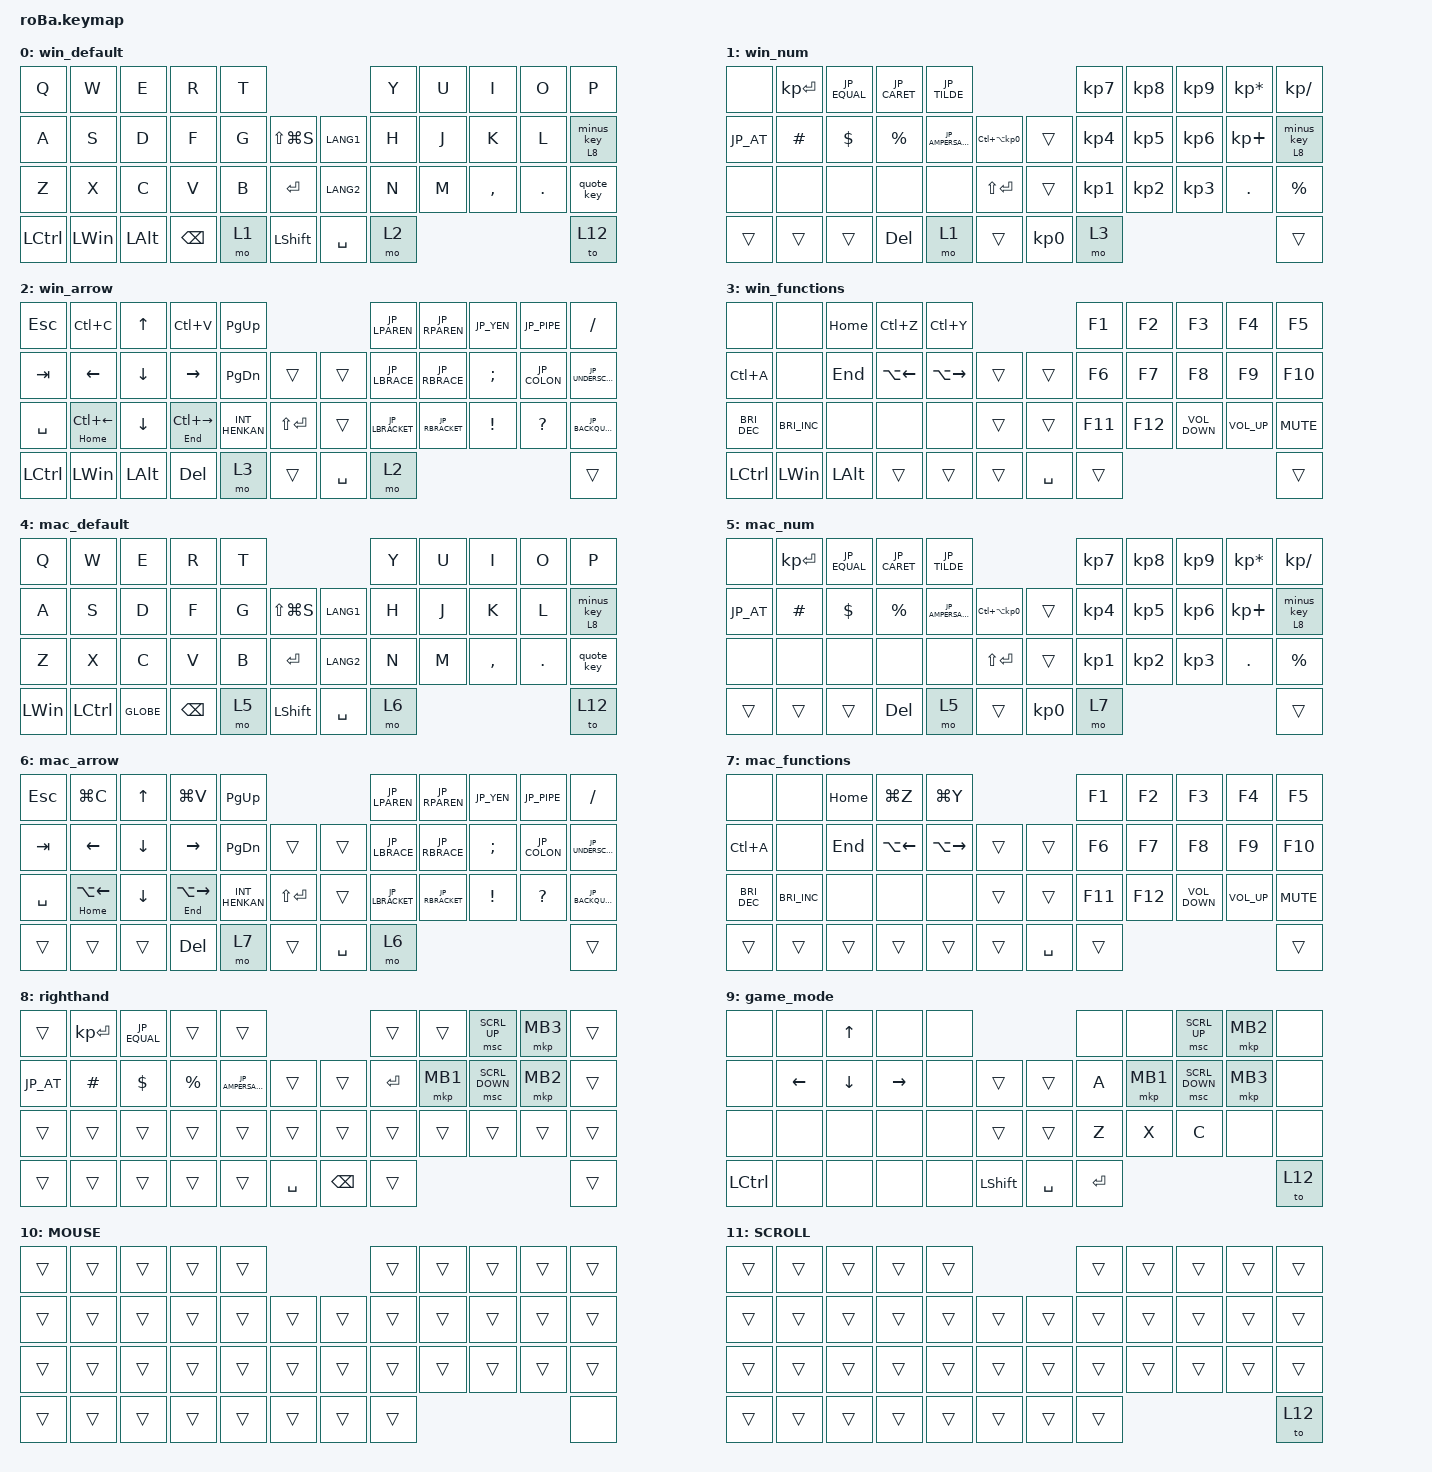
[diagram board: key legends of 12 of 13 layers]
// スクロール量変更の定義を追記

#define ZMK_POINTING_DEFAULT_SCRL_VAL 15

//

#include <behaviors.dtsi>
#include <dt-bindings/zmk/bt.h>
#include <dt-bindings/zmk/keys.h>
#include <dt-bindings/zmk/pointing.h>

// OS設定を日本語キーボードのまま使用するための変換定義

#define JP_DQUOTE       AT                // "
#define JP_AMPERSAND    CARET             // &
#define JP_QUOTE        AMPERSAND         // '
#define JP_EQUAL        UNDER             // =
#define JP_CARET        EQUAL             // ^
#define JP_YEN          0x89              // ¥
#define JP_PLUS         COLON             // +
#define JP_TILDE        PLUS              // ~
#define JP_PIPE         LS(0x89)          // |
#define JP_AT           LEFT_BRACKET      // @
#define JP_COLON        SINGLE_QUOTE      // :
#define JP_ASTERISK     DOUBLE_QUOTES     // *
#define JP_BACKQUOTE    LEFT_BRACE        // `
#define JP_UNDERSCORE   LS(0x87)          // _
#define JP_LBRACKET     RIGHT_BRACKET     // [
#define JP_RBRACKET     BACKSLASH         // ]
#define JP_LPAREN       ASTERISK          // (
#define JP_RPAREN       LEFT_PARENTHESIS  // )
#define JP_LBRACE       RIGHT_BRACE       // {
#define JP_RBRACE       PIPE              // }
#define JP_KANA         LANGUAGE_1        // かな
#define JP_EISU         LANGUAGE_2        // 英数
#define JP_HANZEN       GRAVE             // 半角/全角

//おしまい

&mt {
    flavor = "balanced";
    quick-tap-ms = <0>;
};

&trackball {
    automouse-layer = <10>;
    scroll-layers = <11>;

    // arrows {
    //     layers = <3>;
    //     bindings =
    //         <&kp RIGHT_ARROW>,
    //         <&kp LEFT_ARROW>,
    //         <&kp UP_ARROW>,
    //         <&kp DOWN_ARROW>;
    //     tick = <10>;
    //     wait-ms = <5>;
    //     tap-ms = <5>;
    // };
};

/ {
    combos {
        compatible = "zmk,combos";

        bluetooth_clear {
            bindings = <&bt BT_CLR>;
            key-positions = <42 21 26>;
        };
    };

    macros {
        to_layer_0: to_layer_0 {
            compatible = "zmk,behavior-macro-one-param";
            #binding-cells = <1>;
            bindings = <&to 2 &macro_param_1to1 &kp MACRO_PLACEHOLDER>;
            label = "TO_LAYER_0";
        };
    };

    behaviors {
        lt_to_layer_0: lt_to_layer_0 {
            compatible = "zmk,behavior-hold-tap";
            label = "LAYER_TAP_TO_0";
            bindings = <&mo>, <&to_layer_0>;

            #binding-cells = <2>;
            tapping-term-ms = <200>;
        };

        minus_key: minus_key {
            compatible = "zmk,behavior-mod-morph";
            #binding-cells = <0>;
            bindings = <&kp MINUS>, <&kp JP_EQUAL>;

            mods = <(MOD_LSFT|MOD_RSFT)>;
        };

        lt_minus_key: lt_minus_key {
            compatible = "zmk,behavior-hold-tap";
            label = "LT_MINUS";
            bindings = <&mo>, <&minus_key>;

            #binding-cells = <2>;
            tapping-term-ms = <200>;
        };

        quote_key: quote_key {
            compatible = "zmk,behavior-mod-morph";
            #binding-cells = <0>;
            bindings = <&kp JP_QUOTE>, <&kp JP_DQUOTE>;

            mods = <(MOD_LSFT|MOD_RSFT)>;
        };

        encoder_msc_down_up: encoder_msc_down_up {
            compatible = "zmk,behavior-sensor-rotate";
            label = "ENCODER_MSC_DOWN_UP";
            #sensor-binding-cells = <0>;
            bindings = <&msc MOVE_Y(-40)>, <&msc MOVE_Y(40)>;

            tap-ms = <40>;
        };
    };

    keymap {
        compatible = "zmk,keymap";

        win_default {
            bindings = <
&kp Q      &kp W         &kp E         &kp R          &kp T                                 &kp Y  &kp U  &kp I      &kp O    &kp P
&kp A      &kp S         &kp D         &kp F          &kp G  &kp LS(LG(S))       &kp LANG1  &kp H  &kp J  &kp K      &kp L    &lt_minus_key 8 0
&kp Z      &kp X         &kp C         &kp V          &kp B  &kp ENTER           &kp LANG2  &kp N  &kp M  &kp COMMA  &kp DOT  &quote_key
&kp LCTRL  &kp LEFT_WIN  &kp LEFT_ALT  &kp BACKSPACE  &mo 1  &kp LEFT_SHIFT      &kp SPACE  &mo 2                             &to 12
            >;

            sensor-bindings = <&encoder_msc_down_up>;
        };

        win_num {
            bindings = <
&none      &kp KP_ENTER  &kp JP_EQUAL  &kp JP_CARET  &kp JP_TILDE                                                    &kp KP_NUMBER_7  &kp KP_NUMBER_8  &kp KP_NUMBER_9  &kp KP_MULTIPLY  &kp KP_SLASH
&kp JP_AT  &kp HASH      &kp DOLLAR    &kp PERCENT   &kp JP_AMPERSAND  &kp LC(LA(KP_NUMBER_0))      &trans           &kp KP_NUMBER_4  &kp KP_NUMBER_5  &kp KP_NUMBER_6  &kp KP_PLUS      &lt_minus_key 8 0
&none      &none         &none         &none         &none             &kp LS(ENTER)                &trans           &kp KP_NUMBER_1  &kp KP_NUMBER_2  &kp KP_NUMBER_3  &kp PERIOD       &kp PERCENT
&trans     &trans        &trans        &kp DELETE    &mo 1             &trans                       &kp KP_NUMBER_0  &mo 3                                                               &trans
            >;
        };

        win_arrow {
            bindings = <
&kp ESCAPE  &kp LC(C)                &kp UP_ARROW    &kp LC(V)                &kp PAGE_UP                                   &kp JP_LPAREN    &kp JP_RPAREN    &kp JP_YEN       &kp JP_PIPE   &kp SLASH
&kp TAB     &kp LEFT_ARROW           &kp DOWN_ARROW  &kp RIGHT_ARROW          &kp PAGE_DOWN   &trans             &trans     &kp JP_LBRACE    &kp JP_RBRACE    &kp SEMICOLON    &kp JP_COLON  &kp JP_UNDERSCORE
&kp SPACE   &mt HOME LC(LEFT_ARROW)  &kp DOWN_ARROW  &mt END LC(RIGHT_ARROW)  &kp INT_HENKAN  &kp LS(ENTER)      &trans     &kp JP_LBRACKET  &kp JP_RBRACKET  &kp EXCLAMATION  &kp QUESTION  &kp JP_BACKQUOTE
&kp LCTRL   &kp LEFT_WIN             &kp LEFT_ALT    &kp DELETE               &mo 3           &trans             &kp SPACE  &mo 2                                                            &trans
            >;
        };

        win_functions {
            bindings = <
&none                 &none                 &kp HOME      &kp LC(Z)           &kp LC(Y)                                   &kp F1   &kp F2   &kp F3             &kp F4           &kp F5
&kp LC(A)             &none                 &kp END       &kp LA(LEFT_ARROW)  &kp LA(RIGHT_ARROW)  &trans      &trans     &kp F6   &kp F7   &kp F8             &kp F9           &kp F10
&kp C_BRIGHTNESS_DEC  &kp C_BRIGHTNESS_INC  &none         &none               &none                &trans      &trans     &kp F11  &kp F12  &kp C_VOLUME_DOWN  &kp C_VOLUME_UP  &kp C_MUTE
&kp LCTRL             &kp LEFT_WIN          &kp LEFT_ALT  &trans              &trans               &trans      &kp SPACE  &trans                                                &trans
            >;
        };

        mac_default {
            bindings = <
&kp Q         &kp W      &kp E      &kp R          &kp T                                 &kp Y  &kp U  &kp I      &kp O    &kp P
&kp A         &kp S      &kp D      &kp F          &kp G  &kp LS(LG(S))       &kp LANG1  &kp H  &kp J  &kp K      &kp L    &lt_minus_key 8 0
&kp Z         &kp X      &kp C      &kp V          &kp B  &kp ENTER           &kp LANG2  &kp N  &kp M  &kp COMMA  &kp DOT  &quote_key
&kp LEFT_WIN  &kp LCTRL  &kp GLOBE  &kp BACKSPACE  &mo 5  &kp LEFT_SHIFT      &kp SPACE  &mo 6                             &to 12
            >;

            sensor-bindings = <&encoder_msc_down_up>;
        };

        mac_num {
            bindings = <
&none      &kp KP_ENTER  &kp JP_EQUAL  &kp JP_CARET  &kp JP_TILDE                                                    &kp KP_NUMBER_7  &kp KP_NUMBER_8  &kp KP_NUMBER_9  &kp KP_MULTIPLY  &kp KP_SLASH
&kp JP_AT  &kp HASH      &kp DOLLAR    &kp PERCENT   &kp JP_AMPERSAND  &kp LC(LA(KP_NUMBER_0))      &trans           &kp KP_NUMBER_4  &kp KP_NUMBER_5  &kp KP_NUMBER_6  &kp KP_PLUS      &lt_minus_key 8 0
&none      &none         &none         &none         &none             &kp LS(ENTER)                &trans           &kp KP_NUMBER_1  &kp KP_NUMBER_2  &kp KP_NUMBER_3  &kp PERIOD       &kp PERCENT
&trans     &trans        &trans        &kp DELETE    &mo 5             &trans                       &kp KP_NUMBER_0  &mo 7                                                               &trans
            >;
        };

        mac_arrow {
            bindings = <
&kp ESCAPE  &kp LG(C)                &kp UP_ARROW    &kp LG(V)                &kp PAGE_UP                                   &kp JP_LPAREN    &kp JP_RPAREN    &kp JP_YEN       &kp JP_PIPE   &kp SLASH
&kp TAB     &kp LEFT_ARROW           &kp DOWN_ARROW  &kp RIGHT_ARROW          &kp PAGE_DOWN   &trans             &trans     &kp JP_LBRACE    &kp JP_RBRACE    &kp SEMICOLON    &kp JP_COLON  &kp JP_UNDERSCORE
&kp SPACE   &mt HOME LA(LEFT_ARROW)  &kp DOWN_ARROW  &mt END LA(RIGHT_ARROW)  &kp INT_HENKAN  &kp LS(ENTER)      &trans     &kp JP_LBRACKET  &kp JP_RBRACKET  &kp EXCLAMATION  &kp QUESTION  &kp JP_BACKQUOTE
&trans      &trans                   &trans          &kp DELETE               &mo 7           &trans             &kp SPACE  &mo 6                                                            &trans
            >;
        };

        mac_functions {
            bindings = <
&none                 &none                 &kp HOME  &kp LG(Z)           &kp LG(Y)                                   &kp F1   &kp F2   &kp F3             &kp F4           &kp F5
&kp LC(A)             &none                 &kp END   &kp LA(LEFT_ARROW)  &kp LA(RIGHT_ARROW)  &trans      &trans     &kp F6   &kp F7   &kp F8             &kp F9           &kp F10
&kp C_BRIGHTNESS_DEC  &kp C_BRIGHTNESS_INC  &none     &none               &none                &trans      &trans     &kp F11  &kp F12  &kp C_VOLUME_DOWN  &kp C_VOLUME_UP  &kp C_MUTE
&trans                &trans                &trans    &trans              &trans               &trans      &kp SPACE  &trans                                                &trans
            >;
        };

        righthand {
            bindings = <
&trans     &kp KP_ENTER  &kp JP_EQUAL  &trans       &trans                                          &trans     &trans    &msc SCRL_UP    &mkp MB3  &trans
&kp JP_AT  &kp HASH      &kp DOLLAR    &kp PERCENT  &kp JP_AMPERSAND  &trans         &trans         &kp ENTER  &mkp MB1  &msc SCRL_DOWN  &mkp MB2  &trans
&trans     &trans        &trans        &trans       &trans            &trans         &trans         &trans     &trans    &trans          &trans    &trans
&trans     &trans        &trans        &trans       &trans            &kp SPACE      &kp BACKSPACE  &trans                                         &trans
            >;
        };

        game_mode {
            bindings = <
&none      &none           &kp UP_ARROW    &none            &none                                 &none      &none     &msc SCRL_UP    &mkp MB2  &none
&none      &kp LEFT_ARROW  &kp DOWN_ARROW  &kp RIGHT_ARROW  &none  &trans              &trans     &kp A      &mkp MB1  &msc SCRL_DOWN  &mkp MB3  &none
&none      &none           &none           &none            &none  &trans              &trans     &kp Z      &kp X     &kp C           &none     &none
&kp LCTRL  &none           &none           &none            &none  &kp LEFT_SHIFT      &kp SPACE  &kp ENTER                                      &to 12
            >;
        };

        MOUSE {
            bindings = <
&trans  &trans  &trans  &trans  &trans                      &trans  &trans  &trans  &trans  &trans
&trans  &trans  &trans  &trans  &trans  &trans      &trans  &trans  &trans  &trans  &trans  &trans
&trans  &trans  &trans  &trans  &trans  &trans      &trans  &trans  &trans  &trans  &trans  &trans
&trans  &trans  &trans  &trans  &trans  &trans      &trans  &trans                          &none
            >;
        };

        SCROLL {
            bindings = <
&trans  &trans  &trans  &trans  &trans                      &trans  &trans  &trans  &trans  &trans
&trans  &trans  &trans  &trans  &trans  &trans      &trans  &trans  &trans  &trans  &trans  &trans
&trans  &trans  &trans  &trans  &trans  &trans      &trans  &trans  &trans  &trans  &trans  &trans
&trans  &trans  &trans  &trans  &trans  &trans      &trans  &trans                          &to 12
            >;
        };

        bluetooth {
            bindings = <
&none  &to 0   &none  &none  &none                     &bt BT_SEL 0  &bt BT_SEL 1  &bt BT_SEL 2  &bt BT_SEL 3  &bt BT_SEL 4
&none  &to 11  &none  &none  &to 9  &trans      &none  &none         &none         &none         &none         &none
&none  &none   &none  &none  &none  &none       &none  &none         &to 4         &none         &none         &none
&none  &none   &none  &none  &none  &none       &kp B  &none                                                   &none
            >;
        };
    };
};
